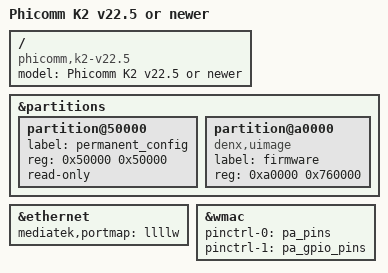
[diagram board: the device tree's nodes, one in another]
#include "mt7620a_phicomm_k2x.dtsi"

/ {
	compatible = "phicomm,k2-v22.5", "ralink,mt7620a-soc";
	model = "Phicomm K2 v22.5 or newer";
};

&partitions {
	partition@50000 {
		label = "permanent_config";
		reg = <0x50000 0x50000>;
		read-only;
	};

	partition@a0000 {
		compatible = "denx,uimage";
		label = "firmware";
		reg = <0xa0000 0x760000>;
	};
};

&ethernet {
	mediatek,portmap = "llllw";
};

&wmac {
	pinctrl-names = "default", "pa_gpio";
	pinctrl-0 = <&pa_pins>;
	pinctrl-1 = <&pa_gpio_pins>;
};
